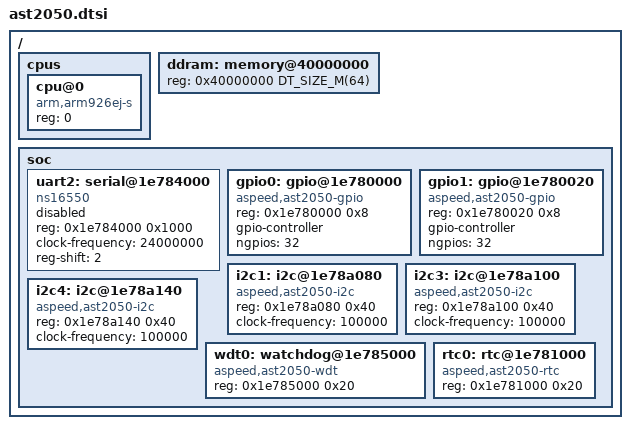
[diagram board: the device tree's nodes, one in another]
/*
 * ASPEED AST2050 (G3) SoC devicetree — ARM926EJ-S.
 * SPDX-License-Identifier: Apache-2.0
 */

#include <arm/armv5.dtsi>
#include <mem.h>

/ {
	#address-cells = <1>;
	#size-cells = <1>;

	cpus {
		#address-cells = <1>;
		#size-cells = <0>;

		cpu@0 {
			device_type = "cpu";
			compatible = "arm,arm926ej-s";
			reg = <0>;
		};
	};

	/* 64 MB DDR2 (SDMC), remapped to the CPU DRAM window. */
	ddram: memory@40000000 {
		device_type = "memory";
		reg = <0x40000000 DT_SIZE_M(64)>;
	};

	soc {
		uart2: serial@1e784000 {
			compatible = "ns16550";
			reg = <0x1e784000 0x1000>;
			clock-frequency = <24000000>;
			reg-shift = <2>;
			status = "disabled";
		};

		/*
		 * AST2050 (G3) GPIO controller at 0x1E780000. The AST2050 datasheet
		 * §23.3 (Base 0x1E78:0000) defines EXACTLY TWO 32-bit data-value
		 * registers: GPIO00 @0x00 (ports A/B/C/D) and GPIO20 @0x20 ("Extended
		 * GPIO Data Value", ports E/F/G/H); direction is at reg+0x04. The
		 * register map ends with the EFGH control block (~0x58) — there are
		 * NO registers at 0x70/0x78/0x80/0x88/0x1E0. Those IJKL/MNOP/QRST/
		 * UVWX/YZAAAB "sets" are an AST2400 (G4) addition and are NOT present
		 * on the AST2050, so they are NOT modelled here (faithfulness — see
		 * device-driver-program #163/#144; cross-checked against the datasheet
		 * GPIO register map). Total register bits = 64 (8 groups A-H x 8), of
		 * which only 46 are bonded on the AST2050/AST1100 package (datasheet
		 * feature table: GPIO max = 46; "8 dedicated + 56 shared"). A node's
		 * reg points at that set's data-value register; ngpios = 32 = one full
		 * 32-bit port (the bonded subset per board is in the §11 GPIO map /
		 * board dts). Only ABCD@0x00 and EFGH@0x20 exist.
		 */
		gpio0: gpio@1e780000 { /* set ABCD */
			compatible = "aspeed,ast2050-gpio";
			reg = <0x1e780000 0x8>;
			gpio-controller;
			#gpio-cells = <2>;
			ngpios = <32>;
			status = "okay";
		};

		gpio1: gpio@1e780020 { /* set EFGH */
			compatible = "aspeed,ast2050-gpio";
			reg = <0x1e780020 0x8>;
			gpio-controller;
			#gpio-cells = <2>;
			ngpios = <32>;
			status = "okay";
		};

		/*
		 * G3/AST2400-compatible I2C controller at 0x1E78A000. Each of the 7
		 * engines is an independent bus; its per-engine register block is at
		 * 0x1E78A000 + 0x40 * (engine + 1). Only the engine used by the smoke
		 * test is modelled here: engine 1 (block 0x1E78A080), which on the
		 * kgpe-d16-bmc QEMU machine carries the Nuvoton/Winbond W83795G
		 * hardware monitor at 7-bit address 0x2F (hw/arm/aspeed.c
		 * kgpe_d16_bmc_i2c_init: i2c_slave_create_simple(get_bus(&soc->i2c, 1),
		 * "w83795", 0x2f); QEMU bus index 1 -> block base 0x1E78A080 via
		 * aspeed_i2c_realize's 0x40*(i+1) mapping). Add sibling engine nodes
		 * (0x1E78A040 engine 0, 0x1E78A0C0 engine 2, ...) as boards need them.
		 * The block is 0x40 bytes; the driver de-asserts the SCU04[2] reset
		 * hold that keeps all engines inert at power-on.
		 */
		i2c1: i2c@1e78a080 { /* engine 1 = schematic I2C2 (QEMU bus 1) */
			compatible = "aspeed,ast2050-i2c";
			reg = <0x1e78a080 0x40>;
			#address-cells = <1>;
			#size-cells = <0>;
			clock-frequency = <100000>;
			status = "okay";
			/* Board-specific slave devices attach in the board dts
			 * (kgpe_d16_bmc: W83795G hwmon @0x2f). */
		};

		/*
		 * Second G3 I2C engine node: engine 3 (block 0x1E78A000 +
		 * 0x40 * (3 + 1) = 0x1E78A100, same 0x40 stride as engine 1
		 * above — see drivers/i2c/i2c_aspeed_g3.c file header). On the
		 * kgpe-d16-bmc QEMU machine this bus carries the two AMD CPU
		 * SB-TSI thermal sensors (hw/arm/aspeed.c kgpe_d16_bmc_i2c_init
		 * lines 619-638: aspeed_i2c_get_bus(&soc->i2c, 3), "sbtsi",
		 * 0x4c/0x4d; QEMU bus index 3 = DT i2c3 = schematic "I2C4").
		 * Each engine independently de-asserts the shared SCU04[2] reset
		 * hold in its init, so a second node is safe.
		 */
		i2c3: i2c@1e78a100 { /* engine 3 = schematic I2C4 (QEMU bus 3) */
			compatible = "aspeed,ast2050-i2c";
			reg = <0x1e78a100 0x40>;
			#address-cells = <1>;
			#size-cells = <0>;
			clock-frequency = <100000>;
			status = "okay";
			/* Board-specific slave devices attach in the board dts
			 * (kgpe_d16_bmc: AMD SB-TSI thermal @0x4c/0x4d). */
		};

		/*
		 * Third G3 I2C engine node: engine 4 (block 0x1E78A000 + 0x40*(4+1)
		 * = 0x1E78A140). On the kgpe-d16-bmc QEMU machine this bus carries the
		 * board FRU EEPROM (U25, Holtek HT24LC08) at 0x54-0x57 (hw/arm/aspeed.c
		 * kgpe_d16_bmc_i2c_init: aspeed_i2c_get_bus(&soc->i2c, 4); QEMU bus 4 =
		 * DT i2c4 = schematic "I2C5"). Shipped BLANK (0xff).
		 */
		i2c4: i2c@1e78a140 { /* engine 4 = schematic I2C5 (QEMU bus 4) */
			compatible = "aspeed,ast2050-i2c";
			reg = <0x1e78a140 0x40>;
			#address-cells = <1>;
			#size-cells = <0>;
			clock-frequency = <100000>;
			status = "okay";
			/* Board-specific slave devices attach in the board dts
			 * (kgpe_d16_bmc: FRU EEPROM @0x54, W83601G DIMM-LED exp @0x18/0x19). */
		};

		/*
		 * G3/AST2400-compatible watchdog timer at 0x1E785000. The AST2050
		 * integrates ONE WDT (the AST2400 grew a second at 0x1E785020; the
		 * kgpe-d16-bmc QEMU SoC models wdts_num = 1). The 0x20-byte block holds
		 * the counter/reload/restart/control registers. Driver:
		 * drivers/watchdog/wdt_aspeed_g3.c. Offsets from QEMU
		 * hw/watchdog/wdt_aspeed.c and the vendor hwreg.h.
		 */
		wdt0: watchdog@1e785000 {
			compatible = "aspeed,ast2050-wdt";
			reg = <0x1e785000 0x20>;
			status = "okay";
		};

		/*
		 * G3 counter-style RTC at 0x1E781000 (datasheet §24; QEMU model
		 * hw/misc/aspeed_rtc_ast2050.c). 0x20-byte register block: COUNTER
		 * 0x00 / RELOAD 0x08 / CONTROL 0x0C / RESTART 0x10 / RESET 0x14.
		 */
		rtc0: rtc@1e781000 {
			compatible = "aspeed,ast2050-rtc";
			reg = <0x1e781000 0x20>;
			status = "okay";
		};
	};
};
